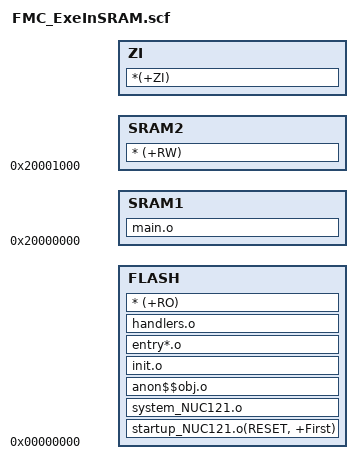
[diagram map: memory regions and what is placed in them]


FLASH 0x00000000
{
    FLASH +0
    {
         startup_NUC121.o(RESET, +First)
         system_NUC121.o
         anon$$obj.o
         init.o
         entry*.o
         handlers.o
		 * (+RO)
    }

	SRAM1 0x20000000
    {  
         main.o
    }

    SRAM2 0x20001000
    {
        * (+RW)
    
    }

	ZI +0
	{
		*(+ZI)
	}

}

